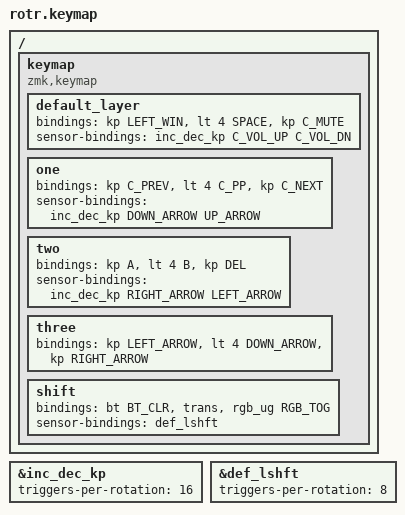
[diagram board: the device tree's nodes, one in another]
#include <behaviors.dtsi>
#include <dt-bindings/zmk/keys.h>
#include <dt-bindings/zmk/rgb.h>
#include <dt-bindings/zmk/bt.h>

&inc_dec_kp {
	triggers-per-rotation = <16>;
};
&def_lshft {
	triggers-per-rotation = <8>;
};

/ {
	keymap {
		compatible = "zmk,keymap";

		default_layer {
			//PREV | PLAY/PAUSE | NEXT
			bindings = <&kp LEFT_WIN &lt 4 SPACE &kp C_MUTE>;
			sensor-bindings = <&inc_dec_kp C_VOL_UP C_VOL_DN>;
		};
		one {
			//PREV | PLAY/PAUSE | NEXT
			bindings = <&kp C_PREV &lt 4 C_PP &kp C_NEXT>;
			sensor-bindings = <&inc_dec_kp DOWN_ARROW UP_ARROW>;
		};
		two {
			//PREV | PLAY/PAUSE | NEXT
			bindings = <&kp A &lt 4 B &kp DEL>;
			sensor-bindings = <&inc_dec_kp RIGHT_ARROW LEFT_ARROW>;
		};
		three {
			//PREV | PLAY/PAUSE | NEXT
			bindings = <&kp LEFT_ARROW &lt 4 DOWN_ARROW &kp RIGHT_ARROW>;
		};
		shift {
			//PREV | PLAY/PAUSE | NEXT
			bindings = <&bt BT_CLR &trans &rgb_ug RGB_TOG>;
			sensor-bindings = <&def_lshft>;
		};
	};
};
